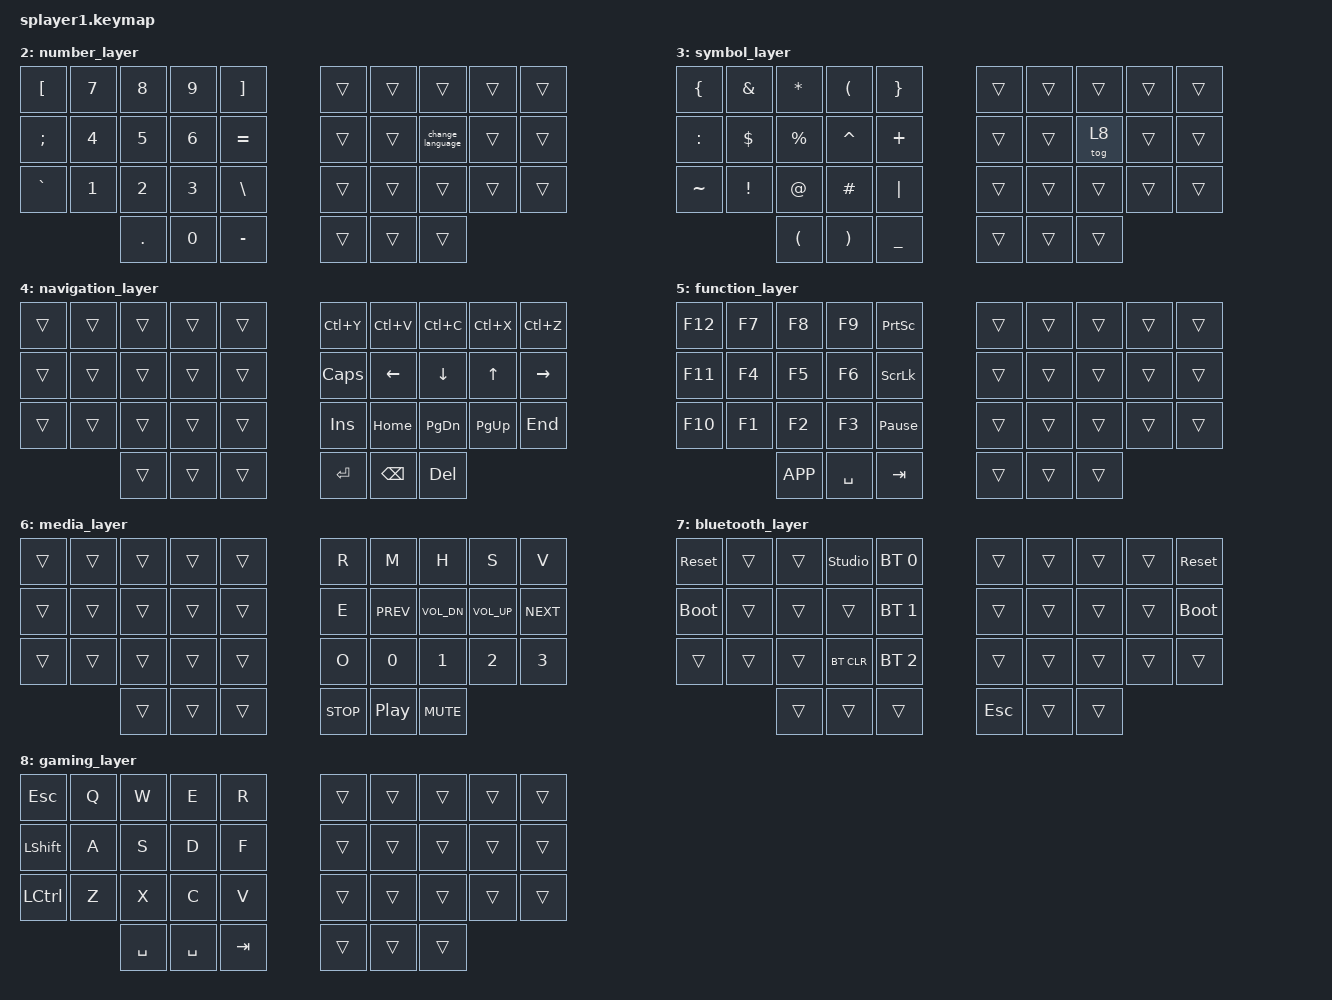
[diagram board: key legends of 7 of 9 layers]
// Copyright (c) 2022 The ZMK Contributors
// SPDX-License-Identifier: MIT

#include <behaviors.dtsi>
#include <dt-bindings/zmk/keys.h>
#include <dt-bindings/zmk/bt.h>

// Home row mods macro
#define HRML(k1,k2,k3,k4) &ht LSHFT k1  &ht LALT k2  &ht LCTRL k3  &ht LGUI k4
#define HRMR(k1,k2,k3,k4) &ht RGUI k1  &ht RCTRL k2  &ht RALT k3  &ht RSHFT k4

/ {
    behaviors {
        ht: hold_tap {
            compatible = "zmk,behavior-hold-tap";
            #binding-cells = <2>;
            flavor = "tap-preferred";
            tapping-term-ms = <220>;
            quick-tap-ms = <150>;
            require-prior-idle-ms = <100>;
            bindings = <&kp>, <&kp>;
        };
    };
    macros {
            change_language: change_language {
            compatible = "zmk,behavior-macro";
            #binding-cells = <0>;
            bindings = <&tog 1>,
                       <&kp LS(LALT)>;
        };
    };

//TODO: UNDERSTAND MEANING:

//    conditional_layers {
//        compatible = "zmk,conditional-layers";
//        tri_layer {
//            if-layers = <1 2>;
//            then-layer = <3>;
//        };
//    };

    keymap {
        compatible = "zmk,keymap";
        default_layer { // layer 0
            bindings = <
//Colemak DH╭──────────┬──────────┬──────────┬──────────┬──────────╮   ╭──────────┬──────────┬──────────┬──────────┬──────────╮
//        //│  Q       │  W       │  F       │  P       │  B       │   │  J       │  L       │  U       │  Y       │  ' "     │
//            &kp Q      &kp W      &kp F      &kp P      &kp B          &kp J      &kp L      &kp U      &kp Y      &kp SQT
//        //├──────────┼──────────┼──────────┼──────────┼──────────┤   ├──────────┼──────────┼──────────┼──────────┼──────────┤
//        //│  A(LSHFT)│  R(LALT) │  S(LCTRL)│  T(WIN)  │  G       │   │  M       │  N(WIN)  │  E(RCTRL)│  I(RALT) │  O(RSHFT)│
//            HRML(A,        R,         S,         T)     &kp G          &kp M      HRMR(N,        E,         I,        O)
//        //├──────────┼──────────┼──────────┼──────────┼──────────┤   ├──────────┼──────────┼──────────┼──────────┼──────────┤
//        //│  Z       │  X       │  C       │ D        │  V       │   │  K       │  H       │ , <      │ . >      │ / ?      │
//            &kp Z      &kp X      &kp C      &kp D      &kp V          &kp K      &kp H      &kp COMMA  &kp DOT    &kp FSLH
//        //╰──────────┴──────────┼──────────┼──────────┼──────────┤   ├──────────┼──────────┼──────────┼──────────┴──────────╯
//        //                      │  ESC     │  SPC     │  TAB     │   │  ENTER   │  BSPC    │  DEL     │
//                                 &lt 6 ESC  &lt 4 SPACE &lt 7 TAB     &lt 3 ENTER &lt 2 BSPC &lt 5 DEL
//        //                      ╰──────────┴──────────┴──────────╯   ╰──────────┴──────────┴──────────╯
//Night   ╭──────────┬──────────┬──────────┬──────────┬──────────╮   ╭──────────┬──────────┬──────────┬──────────┬──────────╮
        //│  B       │  F       │  L       │  K       │  Q       │   │  P       │  G       │  O       │  U       │  . >     │
            &kp B      &kp F      &kp L      &kp K      &kp Q          &kp P      &kp G      &kp O      &kp U      &kp DOT
        //├──────────┼──────────┼──────────┼──────────┼──────────┤   ├──────────┼──────────┼──────────┼──────────┼──────────┤
        //│  N(LSHFT)│  S(LALT) │  H(LCTRL)│  T(WIN)  │  M       │   │  Y       │  C(WIN)  │  A(RCTRL)│  E(RALT) │  I(RSHFT)│
            HRML(N,        S,         H,         T)     &kp M          &kp Y      HRMR(C,        A,         E,        I)
        //├──────────┼──────────┼──────────┼──────────┼──────────┤   ├──────────┼──────────┼──────────┼──────────┼──────────┤
        //│  X       │  V       │  J       │  D       │  Z       │   │  ' "     │  W       │  \       │ / ?      │ , <      │
            &kp X      &kp V      &kp J      &kp D      &kp Z          &kp SQT    &kp W      &kp BSLH   &kp FSLH   &kp COMMA
        //╰──────────┴──────────┼──────────┼──────────┼──────────┤   ├──────────┼──────────┼──────────┼──────────┴──────────╯
        //                      │  ENTER   │  R       │  TAB     │   │  BSPC    │  SPC     │  DEL     │
                                 &lt 6 ENTER &lt 4 R    &lt 7 TAB     &lt 3 BSPC &lt 2 SPACE &lt 5 DEL
        //                      ╰──────────┴──────────┴──────────╯   ╰──────────┴──────────┴──────────╯//TODO: find a fitting place for esc
            >;
    };

        qwerty_layer { // layer 1, used for other languages
            bindings = <
        //╭──────────┬──────────┬──────────┬──────────┬──────────╮   ╭──────────┬──────────┬──────────┬──────────┬──────────╮
        //│  Q       │  W       │  E       │  R       │  T       │   │  Y       │  U       │  I       │  O       │  P       │
            &kp Q      &kp W      &kp E      &kp R      &kp T          &kp Y      &kp U      &kp I      &kp O      &kp P
        //├──────────┼──────────┼──────────┼──────────┼──────────┤   ├──────────┼──────────┼──────────┼──────────┼──────────┤
        //│  A(LSHFT)│  S(LALT) │  D(LCTRL)│  F(WIN)  │  G       │   │  H       │  J(WIN)  │  K(RCTRL)│  L(RALT) │  ;(RSHFT)│
             HRML(A,        S,         D,         F)     &kp G          &kp H      HRMR(J,        K,         L,        SEMI)
        //├──────────┼──────────┼──────────┼──────────┼──────────┤   ├──────────┼──────────┼──────────┼──────────┼──────────┤
        //│  Z       │  X       │  C       │ V        │  B       │   │  N       │  M       │ , <      │ . >      │ / ?      │
            &kp Z      &kp X      &kp C      &kp V      &kp B          &kp N      &kp M      &kp COMMA  &kp DOT    &kp FSLH
        //╰──────────┴──────────┼──────────┼──────────┼──────────┤   ├──────────┼──────────┼──────────┼──────────┴──────────╯
        //                      │  ENTER   │ ' "      │  TAB     │   │  BSPC    │  SPC     │  DEL     │
                                &lt 6 ENTER &lt 4 SQT &lt 7 TAB     &lt 3 BSPC &lt 2 SPACE &lt 5 DEL
        //                      ╰──────────┴──────────┴──────────╯   ╰──────────┴──────────┴──────────╯
            >;
        };

        number_layer { // layer 2
            bindings = <
        //╭──────────┬──────────┬──────────┬──────────┬──────────╮   ╭──────────┬──────────┬──────────┬──────────┬──────────╮
        //│  [       │  7       │  8       │  9       │  ]       │   │          │          │          │          │          │
            &kp LBKT   &kp N7     &kp N8     &kp N9     &kp RBKT        &trans     &trans     &trans     &trans     &trans
        //├──────────┼──────────┼──────────┼──────────┼──────────┤   ├──────────┼──────────┼──────────┼──────────┼──────────┤
        //│  ;       │  4       │  5       │  6       │  =       │   │          │          │          │          │          │
            &kp SEMI   &kp N4     &kp N5     &kp N6     &kp EQUAL       &trans     &trans     &change_language    &trans     &trans
        //├──────────┼──────────┼──────────┼──────────┼──────────┤   ├──────────┼──────────┼──────────┼──────────┼──────────┤
        //│  `       │  1       │  2       │ 3        │  \       │   │          │          │          │          │          │
           &kp GRAVE   &kp N1     &kp N2     &kp N3     &kp BSLH        &trans     &trans     &trans     &trans     &trans
        //╰──────────┴──────────┼──────────┼──────────┼──────────┤   ├──────────┼──────────┼──────────┼──────────┴──────────╯
        //                      │ . > DOT! │  0       │  -       │   │          │ACTIVATOR │          │
                                  &kp DOT    &kp N0     &kp MINUS       &trans     &trans     &trans
        //                      ╰──────────┴──────────┴──────────╯   ╰──────────┴──────────┴──────────╯
            >;
        };

        symbol_layer { // layer 3
            bindings = <
        //╭──────────┬──────────┬──────────┬──────────┬──────────╮   ╭──────────┬──────────┬──────────┬──────────┬──────────╮
        //│  {       │  &       │  *       │  (       │  }       │   │          │          │          │          │          │
            &kp LBRC   &kp AMPS   &kp ASTRK  &kp LPAR   &kp RBRC        &trans     &trans     &trans     &trans     &trans
        //├──────────┼──────────┼──────────┼──────────┼──────────┤   ├──────────┼──────────┼──────────┼──────────┼──────────┤
        //│  :       │  $       │  %       │  ^       │  +       │   │          │          │          │          │          │
            &kp COLON  &kp DLLR   &kp PRCNT  &kp CARET  &kp PLUS        &trans     &trans     &tog 8     &trans     &trans
        //├──────────┼──────────┼──────────┼──────────┼──────────┤   ├──────────┼──────────┼──────────┼──────────┼──────────┤
        //│  ~       │  !       │  @       │  #       │  |       │   │          │          │          │          │          │
            &kp TILDE  &kp EXCL   &kp AT     &kp HASH   &kp PIPE        &trans     &trans     &trans     &trans     &trans
        //╰──────────┴──────────┼──────────┼──────────┼──────────┤   ├──────────┼──────────┼──────────┼──────────┴──────────╯
        //                      │  (       │  )       │  _       │   │ACTIVATOR │          │          │
                                  &kp LPAR   &kp RPAR   &kp UNDER       &trans     &trans     &trans
        //                      ╰──────────┴──────────┴──────────╯   ╰──────────┴──────────┴──────────╯
            >;
        };

        navigation_layer { // layer 4
            bindings = <
        //╭──────────┬──────────┬──────────┬──────────┬──────────╮   ╭──────────┬──────────┬──────────┬──────────┬──────────╮
        //│          │          │          │          │          │   │          │          │          │          │          │
            &trans     &trans     &trans     &trans     &trans         &kp LC(Y)  &kp LC(V)  &kp LC(C)  &kp LC(X)  &kp LC(Z)
        //├──────────┼──────────┼──────────┼──────────┼──────────┤   ├──────────┼──────────┼──────────┼──────────┼──────────┤
        //│          │          │          │          │          │   │ Caps Lock│  ⬅      │   ⬇       │  ⬆       │ ➡       │
            &trans     &trans     &trans     &trans     &trans         &kp CAPS   &kp LEFT   &kp DOWN   &kp UP     &kp RIGHT
        //├──────────┼──────────┼──────────┼──────────┼──────────┤   ├──────────┼──────────┼──────────┼──────────┼──────────┤
        //│          │          │          │          │          │   │  Insert  │  Home    │ Page Down│  Page Up │  End     │
            &trans     &trans     &trans     &trans     &trans         &kp INS    &kp HOME   &kp PG_DN  &kp PG_UP  &kp END
        //╰──────────┴──────────┼──────────┼──────────┼──────────┤   ├──────────┼──────────┼──────────┼──────────┴──────────╯
        //                      │          │ACTIVATOR │          │   │  ENTER   │  BSPC    │  DEL     │
                                  &trans     &trans     &trans         &kp ENTER  &kp BSPC   &kp DEL
        //                      ╰──────────┴──────────┴──────────╯   ╰──────────┴──────────┴──────────╯
           >;
        };

        function_layer { // layer 5
            bindings = <
        //╭──────────┬──────────┬──────────┬──────────┬──────────╮   ╭──────────┬──────────┬──────────┬──────────┬──────────╮
        //│  F12     │  F7      │  F8      │  F9      │  PSCRN   │   │          │          │          │          │          │
            &kp F12    &kp F7     &kp F8     &kp F9     &kp PSCRN       &trans     &trans     &trans     &trans     &trans
        //├──────────┼──────────┼──────────┼──────────┼──────────┤   ├──────────┼──────────┼──────────┼──────────┼──────────┤
        //│  F11     │  F4      │  F5      │  F6      │SCROLLLOCK│   │          │          │          │          │          │
            &kp F11    &kp F4     &kp F5     &kp F6     &kp SLCK        &trans     &trans     &trans     &trans     &trans
        //├──────────┼──────────┼──────────┼──────────┼──────────┤   ├──────────┼──────────┼──────────┼──────────┼──────────┤
        //│  F10     │  F1      │  F2      │  F3      PAUSE_BREAK│   │          │          │          │          │          │
            &kp F10    &kp F1     &kp F2     &kp F3   &kp PAUSE_BREAK   &trans     &trans     &trans     &trans     &trans
        //╰──────────┴──────────┼──────────┼──────────┼──────────┤   ├──────────┼──────────┼──────────┼──────────┴──────────╯
        //                      │ OPTIONS  │  SPACE   │  TAB     │   │          │          │ACTIVATOR │
                                  &kp K_APP  &kp SPACE  &kp TAB         &trans     &trans     &trans
        //                      ╰──────────┴──────────┴──────────╯   ╰──────────┴──────────┴──────────╯
            >;
        };

        media_layer { // layer 6
            bindings = <
        //╭──────────┬──────────┬──────────┬──────────┬──────────╮   ╭──────────┬──────────┬──────────┬──────────┬──────────╮
        //│          │          │          │          │          │   │  R       │  M       │  H       │  S       │  V       │
            &trans     &trans     &trans     &trans     &trans         &kp R      &kp M      &kp H      &kp S      &kp V
        //├──────────┼──────────┼──────────┼──────────┼──────────┤   ├──────────┼──────────┼──────────┼──────────┼──────────┤
        //│          │          │          │          │          │   │  E       │  ⏮       │  🔉      │  🔊      │  ⏭       │
            &trans     &trans     &trans     &trans     &trans         &kp E    &kp C_PREV &kp C_VOL_DN &kp C_VOL_UP &kp C_NEXT
        //├──────────┼──────────┼──────────┼──────────┼──────────┤   ├──────────┼──────────┼──────────┼──────────┼──────────┤
        //│          │          │          │          │          │   │  O       │  0       │  1       │  2       │  3       │
            &trans     &trans     &trans     &trans     &trans         &kp O      &kp N0     &kp N1     &kp N2     &kp N3
        //╰──────────┴──────────┼──────────┼──────────┼──────────┤   ├──────────┼──────────┼──────────┼──────────┴──────────╯
        //                      │ACTIVATOR │          │          │   │  STOP    │PLAY/PAUSE│  🔇      │
                                  &trans     &trans     &trans         &kp C_STOP &kp C_PP   &kp C_MUTE
        //                      ╰──────────┴──────────┴──────────╯   ╰──────────┴──────────┴──────────╯ //TODO: REWIND MIGHT BE A GOOD ADDITION!
            >;
        };

        bluetooth_layer { //layer 7
            bindings = <
        //╭──────────┬──────────┬──────────┬──────────┬──────────╮   ╭──────────┬──────────┬──────────┬──────────┬──────────╮
        //│ RESET    │          │          │zmk studio│PROFILE 0 │   │          │          │          │          │  RESET   │
           &sys_reset  &trans     &trans &studio_unlock &bt BT_SEL 0    &trans     &trans     &trans     &trans    &sys_reset
        //├──────────┼──────────┼──────────┼──────────┼──────────┤   ├──────────┼──────────┼──────────┼──────────┼──────────┤
        //│BOOTLOADER│          │          │          │PROFILE 1 │   │          │          │          │          │BOOTLOADER│
          &bootloader  &trans     &trans     &trans    &bt BT_SEL 1    &trans     &trans     &trans     &trans    &bootloader
        //├──────────┼──────────┼──────────┼──────────┼──────────┤   ├──────────┼──────────┼──────────┼──────────┼──────────┤
        //│          │          │          │ CLEAR BT │PROFILE 2 │   │          │          │          │          │          │
            &trans     &trans     &trans    &bt BT_CLR &bt BT_SEL 2    &trans     &trans     &trans     &trans     &trans
        //╰──────────┴──────────┼──────────┼──────────┼──────────┤   ├──────────┼──────────┼──────────┼──────────┴──────────╯
        //                      │          │          │ACTIVATOR │   │          │          │          │
                                  &trans     &trans     &trans         &kp ESC    &trans     &trans
        //                      ╰──────────┴──────────┴──────────╯   ╰──────────┴──────────┴──────────╯
            >;
        };

        gaming_layer { // layer 8, activated from layer 3
            bindings = <
        //╭──────────┬──────────┬──────────┬──────────┬──────────╮   ╭──────────┬──────────┬──────────┬──────────┬──────────╮
        //│  ESC     │  Q       │  W       │  E       │  R       │   │          │          │          │          │          │
            &kp ESC    &kp Q      &kp W      &kp E      &kp R          &trans     &trans     &trans     &trans     &trans
        //├──────────┼──────────┼──────────┼──────────┼──────────┤   ├──────────┼──────────┼──────────┼──────────┼──────────┤
        //│  LSHFT   │  A       │  S       │  D       │  F       │   │          │          │          │          │          │
            &kp LSHFT  &kp A      &kp S      &kp D      &kp F          &trans     &trans     &trans     &trans     &trans
        //├──────────┼──────────┼──────────┼──────────┼──────────┤   ├──────────┼──────────┼──────────┼──────────┼──────────┤
        //│  LCTRL   │  Z       │  X       │  C       │  V       │   │          │          │          │          │          │
            &kp LCTRL  &kp Z      &kp X      &kp C      &kp V          &trans     &trans     &trans     &trans     &trans
        //╰──────────┴──────────┼──────────┼──────────┼──────────┤   ├──────────┼──────────┼──────────┼──────────┴──────────╯
        //                      │  SPC     │  SPC     │  TAB     │   │          │          │          │
                                  &kp SPACE  &kp SPACE  &kp TAB        &trans     &trans     &trans
        //                      ╰──────────┴──────────┴──────────╯   ╰──────────┴──────────┴──────────╯
            >;
        };
    };
};
